# STM32N655 register map
File version: 1.0
CPU: CM55 r0p1, little endian, no MPU, FPU, vendor SysTick, 8 interrupt priority bits
Registers are 32-bit, read-write, reset 0x0 unless marked. A register's access mark holds for its fields unless they carry their own. Offsets are from the block's base; [hi:lo] are bit positions; {n}, {i} and the like mark numbered series; 'fields as' and 'values as' point back to an identical list.

## ETH — Ethernet address block description
Base 0x48036000
Same registers: ETH_S 0x58036000
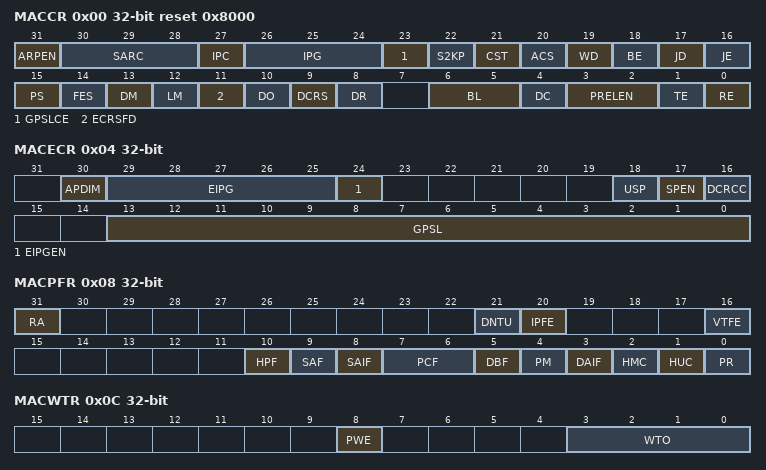
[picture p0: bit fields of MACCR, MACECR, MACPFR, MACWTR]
0x00 MACCR reset 0x8000 — Operating mode configuration register
  [31] ARPEN — ARP Offload Enable
  [30:28] SARC — Source Address Insertion or Replacement Control
  [27] IPC — Checksum Offload
  [26:24] IPG — Inter-Packet Gap
  [23] GPSLCE — Giant Packet Size Limit Control Enable
  [22] S2KP — IEEE 802.3as Support for 2K Packets
  [21] CST — CRC stripping for Type packets
  [20] ACS — Automatic Pad or CRC Stripping
  [19] WD — Watchdog Disable
  [18] BE — Packet Burst Enable
  [17] JD — Jabber Disable
  [16] JE — Jumbo Packet Enable
  [15] PS — Port Select
  [14] FES — MAC Speed
  [13] DM — Duplex Mode
  [12] LM — Loopback Mode
  [11] ECRSFD — Enable Carrier Sense Before Transmission in Full-duplex mode
  [10] DO — Disable Receive Own
  [9] DCRS — Disable Carrier Sense During Transmission
  [8] DR — Disable Retry
  [6:5] BL — Back-Off Limit
  [4] DC — Deferral Check
  [3:2] PRELEN — Preamble Length for Transmit packets
  [1] TE — Transmitter Enable
  [0] RE — Receiver Enable
0x04 MACECR — Extended operating mode configuration register
  [30] APDIM — ARP Packet Drop if IP Address Mismatch
  [29:25] EIPG — Extended Inter-Packet Gap
  [24] EIPGEN — Extended Inter-Packet Gap Enable
  [18] USP — Unicast Slow Protocol Packet Detect
  [17] SPEN — Slow Protocol Detection Enable
  [16] DCRCC — Disable CRC Checking for Received Packets
  [13:0] GPSL — Giant Packet Size Limit
0x08 MACPFR — Packet filtering control register
  [31] RA — Receive All
  [21] DNTU — Drop Non-TCP/UDP over IP Packets
  [20] IPFE — Layer 3 and Layer 4 Filter Enable
  [16] VTFE — VLAN Tag Filter Enable
  [10] HPF — Hash or Perfect Filter
  [9] SAF — Source Address Filter Enable
  [8] SAIF — SA Inverse Filtering
  [7:6] PCF — Pass Control Packets
  [5] DBF — Disable Broadcast Packets
  [4] PM — Pass All Multicast
  [3] DAIF — DA Inverse Filtering
  [2] HMC — Hash Multicast
  [1] HUC — Hash Unicast
  [0] PR — Promiscuous Mode
0x0C MACWTR — Watchdog timeout register
  [8] PWE — Programmable Watchdog Enable
  [3:0] WTO — Watchdog Timeout
0x10 MACHT0R — Hash Table 0 register
  [31:0] HT31T0 — MAC Hash Table First 32 Bits
0x14 MACHT1R — Hash Table 1 register
  [31:0] HT63T32 — MAC Hash Table Second 32 Bits
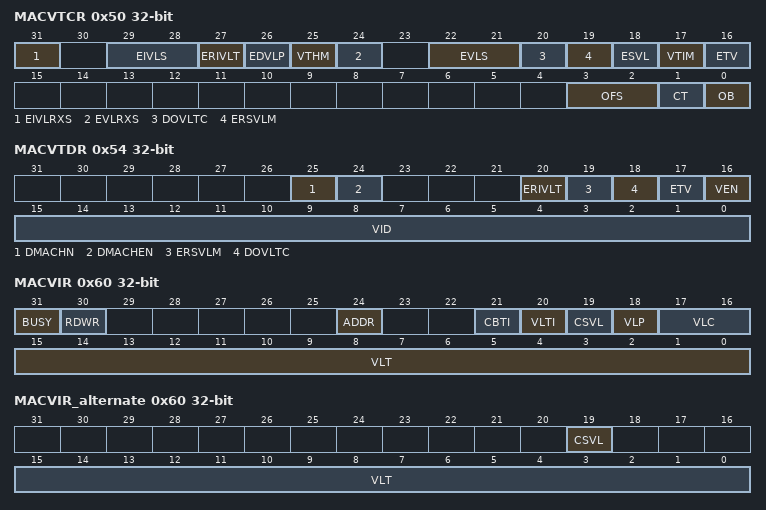
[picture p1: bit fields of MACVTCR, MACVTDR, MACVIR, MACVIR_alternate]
0x50 MACVTCR — VLAN tag Control register
  [31] EIVLRXS — Enable Inner VLAN Tag in Rx Status
  [29:28] EIVLS — Enable Inner VLAN Tag Stripping on Receive
  [27] ERIVLT — Enable Inner VLAN Tag
  [26] EDVLP — Enable Double VLAN Processing
  [25] VTHM — VLAN Tag Hash Table Match Enable
  [24] EVLRXS — Enable VLAN Tag in Rx status
  [22:21] EVLS — Enable VLAN Tag Stripping on Receive
  [20] DOVLTC — Disable VLAN Type Check
  [19] ERSVLM — Enable Receive S-VLAN Match
  [18] ESVL — Enable S-VLAN
  [17] VTIM — VLAN Tag Inverse Match Enable
  [16] ETV — Enable 12-Bit VLAN Tag Comparison
  [3:2] OFS — Offset
  [1] CT — Command Type
  [0] OB — Operation Busy
0x54 MACVTDR — VLAN tag data register
  [25] DMACHN — DMA Channel Number
  [24] DMACHEN — DMA Channel Number Enable
  [20] ERIVLT — Enable Inner VLAN Tag Comparison
  [19] ERSVLM — Enable S-VLAN Match for received Frames
  [18] DOVLTC — Disable VLAN Type Comparison
  [17] ETV — 12-bit or 16-bit VLAN comparison
  [16] VEN — VLAN Tag Enable
  [15:0] VID — VLAN Tag ID
0x58 MACVHTR — VLAN Hash table register
  [15:0] VLHT — VLAN Hash Table
0x60 MACVIR access per field — VLAN inclusion register
  [31] BUSY ro
  [30] RDWR rw — Read write control
  [24] ADDR rw — Address
  [21] CBTI rw — Channel based tag insertion
  [20] VLTI rw — VLAN Tag Input
  [19] CSVL rw — C-VLAN or S-VLAN
  [18] VLP rw — VLAN Priority Control
  [17:16] VLC rw — VLAN Tag Control in Transmit Packets
  [15:0] VLT rw — VLAN Tag for Transmit Packets
0x60 MACVIR_alternate (alternate view of MACVIR) — VLAN inclusion register
  [19] CSVL — C-VLAN or S-VLAN
  [15:0] VLT — VLAN Tag for Transmit Packets
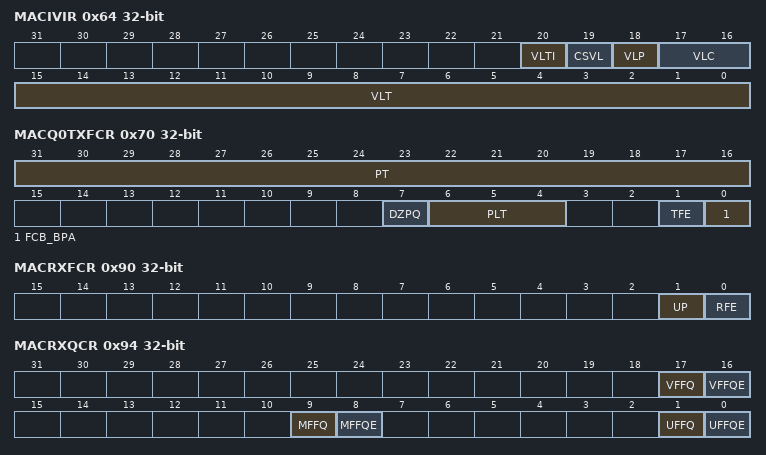
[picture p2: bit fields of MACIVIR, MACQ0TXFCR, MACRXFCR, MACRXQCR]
0x64 MACIVIR — Inner VLAN inclusion register
  [20] VLTI — VLAN Tag Input
  [19] CSVL — C-VLAN or S-VLAN
  [18] VLP — VLAN Priority Control
  [17:16] VLC — VLAN Tag Control in Transmit Packets
  [15:0] VLT — VLAN Tag for Transmit Packets
0x70 MACQ0TXFCR — Tx Queue 0 flow control register
  [31:16] PT — Pause Time
  [7] DZPQ — Disable Zero-Quanta Pause
  [6:4] PLT — Pause Low Threshold
  [1] TFE — Transmit Flow Control Enable
  [0] FCB_BPA — Flow Control Busy or Backpressure Activate
0x90 MACRXFCR — Rx flow control register
  [1] UP — Unicast Pause Packet Detect
  [0] RFE — Receive Flow Control Enable
0x94 MACRXQCR — Rx Queue control register
  [17] VFFQ — VLAN Tag Filter Fail Packets Queue
  [16] VFFQE — VLAN Tag Filter Fail Packets Queuing Enable
  [9] MFFQ — Multicast Address Filter Fail Packets Queue.
  [8] MFFQE — Multicast Address Filter Fail Packets Queuing Enable.
  [1] UFFQ — Unicast Address Filter Fail Packets Queue.
  [0] UFFQE — Unicast Address Filter Fail Packets Queuing Enable.
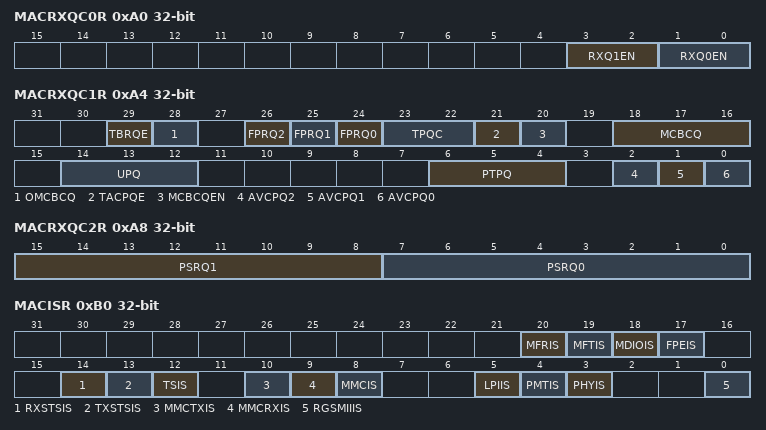
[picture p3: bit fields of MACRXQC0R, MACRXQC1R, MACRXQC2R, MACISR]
0xA0 MACRXQC0R — Rx queue control 0 register
  [3:2] RXQ1EN — Receive Queue 1 Enable
  [1:0] RXQ0EN — Receive Queue 0 Enable
0xA4 MACRXQC1R — Rx queue control 1 register
  [29] TBRQE — Type Field Based Rx Queuing Enable
  [28] OMCBCQ — Overriding MC-BC queue priority select
  [26] FPRQ2 — Frame Preemption Residue Queue
  [25] FPRQ1 — Frame Preemption Residue Queue
  [24] FPRQ0 — Frame Preemption Residue Queue
  [23:22] TPQC — Tagged PTP over Ethernet Packets Queuing Control
  [21] TACPQE — Tagged AV Control Packets Queuing Enable
  [20] MCBCQEN — Multicast and Broadcast Queue Enable
  [18:16] MCBCQ — Multicast and Broadcast Queue
  [14:12] UPQ — Untagged Packet Queue
  [6:4] PTPQ — PTP Packets Queue
  [2] AVCPQ2 — AV Untagged Control Packets Queue
  [1] AVCPQ1 — AV Untagged Control Packets Queue
  [0] AVCPQ0 — AV Untagged Control Packets Queue
0xA8 MACRXQC2R — Rx queue control 2 register
  [15:8] PSRQ1 — Priorities Selected in the Receive Queue 1
  [7:0] PSRQ0 — Priorities Selected in the Receive Queue 0
0xB0 MACISR access per field — Interrupt status register
  [20] MFRIS ro — MMC FPE Receive Interrupt Status
  [19] MFTIS ro — MMC FPE Transmit Interrupt Status
  [18] MDIOIS rw read-clears — MDIO Interrupt Status
  [17] FPEIS ro — Frame Preemption Interrupt Status
  [14] RXSTSIS rw read-clears — Receive Status Interrupt
  [13] TXSTSIS rw read-clears — Transmit Status Interrupt
  [12] TSIS rw read-clears — Timestamp Interrupt Status
  [10] MMCTXIS ro — MMC Transmit Interrupt Status
  [9] MMCRXIS ro — MMC Receive Interrupt Status
  [8] MMCIS ro — MMC Interrupt Status
  [5] LPIIS ro — LPI Interrupt Status
  [4] PMTIS ro — PMT Interrupt Status
  [3] PHYIS ro — PHY Interrupt
  [0] RGSMIIIS ro — RGMII Interrupt Status
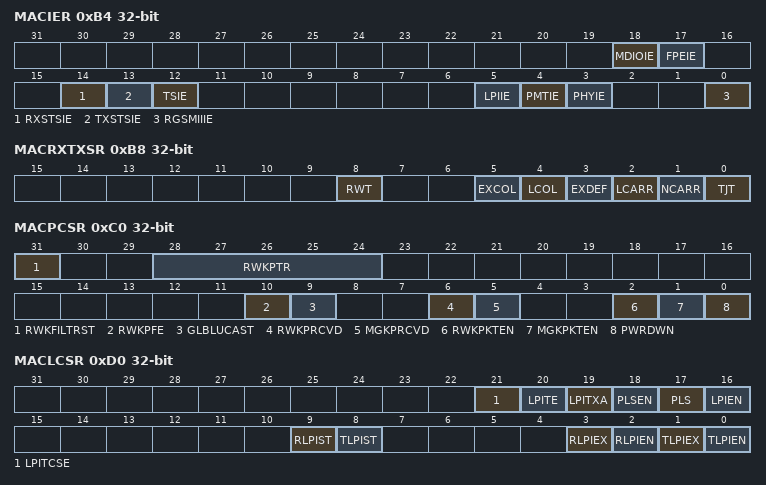
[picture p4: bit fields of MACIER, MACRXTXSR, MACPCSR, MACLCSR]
0xB4 MACIER — Interrupt enable register
  [18] MDIOIE — MDIO Interrupt Enable
  [17] FPEIE — Frame Preemption Interrupt Enable
  [14] RXSTSIE — Receive Status Interrupt Enable
  [13] TXSTSIE — Transmit Status Interrupt Enable
  [12] TSIE — Timestamp Interrupt Enable
  [5] LPIIE — LPI Interrupt Enable
  [4] PMTIE — PMT Interrupt Enable
  [3] PHYIE — PHY Interrupt Enable
  [0] RGSMIIIE — RGMII Interrupt Enable
0xB8 MACRXTXSR — Rx Tx status register
  [8] RWT read-clears — Receive Watchdog Timeout
  [5] EXCOL read-clears — Excessive Collisions
  [4] LCOL read-clears — Late Collision
  [3] EXDEF read-clears — Excessive Deferral
  [2] LCARR read-clears — Loss of Carrier
  [1] NCARR read-clears — No Carrier
  [0] TJT read-clears — Transmit Jabber Timeout
0xC0 MACPCSR access per field — PMT control status register
  [31] RWKFILTRST rw — Remote wake-up Packet Filter Register Pointer Reset
  [28:24] RWKPTR ro — Remote wake-up FIFO Pointer
  [10] RWKPFE rw — Remote wake-up Packet Forwarding Enable
  [9] GLBLUCAST rw — Global Unicast
  [6] RWKPRCVD ro — Remote wake-up Packet Received
  [5] MGKPRCVD rw read-clears — Magic Packet Received
  [2] RWKPKTEN rw — Remote wake-up Packet Enable
  [1] MGKPKTEN rw — Magic Packet Enable
  [0] PWRDWN rw — Power Down
0xC4 MACRWKPFR — Remote wake-up packet filter register
  [31:0] MACRWKPFR — Remote wake-up packet filter
0xD0 MACLCSR access per field — LPI control and status register
  [21] LPITCSE rw — LPI Tx Clock Stop Enable
  [20] LPITE rw — LPI Timer Enable
  [19] LPITXA rw — LPI Tx Automate
  [18] PLSEN rw — PHY Link Status Enable
  [17] PLS rw — PHY Link Status
  [16] LPIEN rw — LPI Enable
  [9] RLPIST ro — Receive LPI State
  [8] TLPIST ro — Transmit LPI State
  [3] RLPIEX ro — Receive LPI Exit
  [2] RLPIEN ro — Receive LPI Entry
  [1] TLPIEX ro — Transmit LPI Exit
  [0] TLPIEN ro — Transmit LPI Entry
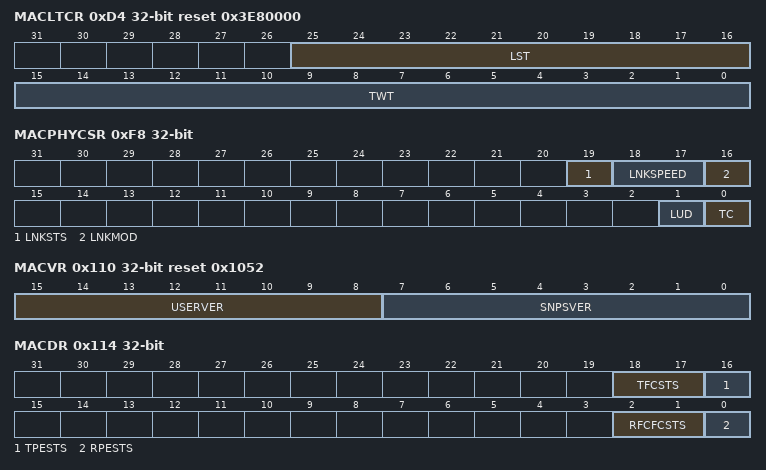
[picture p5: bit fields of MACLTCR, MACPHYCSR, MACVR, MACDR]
0xD4 MACLTCR reset 0x3E80000 — LPI timers control register
  [25:16] LST — LPI LS Timer
  [15:0] TWT — LPI TW Timer
0xD8 MACLETR — LPI entry timer register
  [19:0] LPIET — LPI Entry Timer
0xDC MAC1USTCR — One-microsecond-tick counter register
  [11:0] TIC_1US_CNTR — 1 s tick Counter
0xF8 MACPHYCSR access per field — PHYIF control status register
  [19] LNKSTS ro — Link Status
  [18:17] LNKSPEED ro — Link Speed
  [16] LNKMOD ro — Link Mode
  [1] LUD rw — Link Up or Down
  [0] TC rw — Transmit Configuration in RGMII
0x110 MACVR ro reset 0x1052 — Version register
  [15:8] USERVER — ST-defined version
  [7:0] SNPSVER — IP version
0x114 MACDR ro — Debug register
  [18:17] TFCSTS — MAC Transmit Packet Controller Status
  [16] TPESTS — MAC GMII or MII Transmit Protocol Engine Status
  [2:1] RFCFCSTS — MAC Receive Packet Controller FIFO Status
  [0] RPESTS — MAC GMII or MII Receive Protocol Engine Status
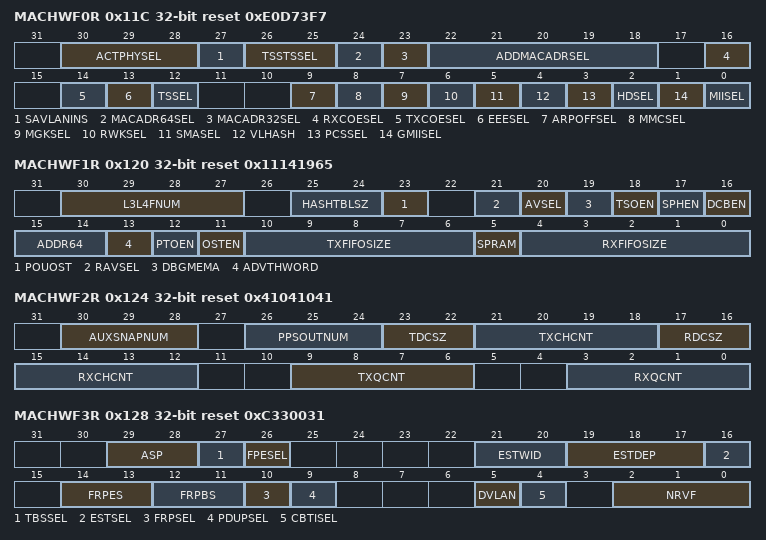
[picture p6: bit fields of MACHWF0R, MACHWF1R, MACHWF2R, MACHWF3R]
0x11C MACHWF0R ro reset 0xE0D73F7 — HW feature 0 register
  [30:28] ACTPHYSEL — Active PHY Selected
  [27] SAVLANINS — Source Address or VLAN Insertion Enable
  [26:25] TSSTSSEL — Timestamp System Time Source
  [24] MACADR64SEL — MAC Addresses 64-127 Selected
  [23] MACADR32SEL — MAC Addresses 32-63 Selected
  [22:18] ADDMACADRSEL — MAC Addresses 1-31 Selected
  [16] RXCOESEL — Receive Checksum Offload Enabled
  [14] TXCOESEL — Transmit Checksum Offload Enabled
  [13] EEESEL — Energy Efficient Ethernet Enabled
  [12] TSSEL — IEEE 1588-2008 Timestamp Enabled
  [9] ARPOFFSEL — ARP Offload Enabled
  [8] MMCSEL — RMON Module Enable
  [7] MGKSEL — PMT Magic Packet Enable
  [6] RWKSEL — PMT Remote wake-up Packet Enable
  [5] SMASEL — SMA (MDIO) Interface
  [4] VLHASH — VLAN Hash Filter Selected
  [3] PCSSEL — PCS Registers (TBI, SGMII, or RTBI PHY interface)
  [2] HDSEL — Half-duplex Support
  [1] GMIISEL — 1000 Mbps Support
  [0] MIISEL — 10 or 100 Mbps Support
0x120 MACHWF1R ro reset 0x11141965 — HW feature 1 register
  [30:27] L3L4FNUM — Total number of L3 or L4 Filters
  [25:24] HASHTBLSZ — Hash Table Size
  [23] POUOST — One Step for PTP over UDP/IP Feature Enable
  [21] RAVSEL — Rx Side Only AV Feature Enable
  [20] AVSEL — AV Feature Enable
  [19] DBGMEMA — DMA Debug Registers Enable
  [18] TSOEN — TCP Segmentation Offload Enable
  [17] SPHEN — Split Header Feature Enable
  [16] DCBEN — DCB Feature Enable
  [15:14] ADDR64 — Address width
  [13] ADVTHWORD — IEEE 1588 High Word Register Enable
  [12] PTOEN — PTP Offload Enable
  [11] OSTEN — One-Step Timestamping Enable
  [10:6] TXFIFOSIZE — MTL Transmit FIFO Size
  [5] SPRAM — Single Port RAM Enable
  [4:0] RXFIFOSIZE — MTL Receive FIFO Size
0x124 MACHWF2R ro reset 0x41041041 — HW feature 2 register
  [30:28] AUXSNAPNUM — Number of Auxiliary Snapshot Inputs
  [26:24] PPSOUTNUM — Number of PPS Outputs
  [23:22] TDCSZ — Tx DMA Descriptor Cache Size in terms of 16-byte descriptors
  [21:18] TXCHCNT — Number of DMA Transmit Channels
  [17:16] RDCSZ — Rx DMA Descriptor Cache Size in terms of 16-byte descriptors
  [15:12] RXCHCNT — Number of DMA Receive Channels
  [9:6] TXQCNT — Number of MTL Transmit Queues
  [3:0] RXQCNT — Number of MTL Receive Queues
0x128 MACHWF3R ro reset 0xC330031 — HW feature 3 register
  [29:28] ASP — Automotive Safety Package
  [27] TBSSEL — Time-based scheduling Enable
  [26] FPESEL — Frame Preemption Enable
  [21:20] ESTWID — Width of the Time Interval field in the Gate Control List
  [19:17] ESTDEP — Depth of the Gate Control List
  [16] ESTSEL — Enhancements to Scheduled Traffic Enable
  [14:13] FRPES — Flexible Receive Parser Table Entries size
  [12:11] FRPBS — Flexible Receive Parser Buffer size
  [10] FRPSEL — Flexible Receive Parser Selected
  [9] PDUPSEL — Broadcast/Multicast Packet Duplication
  [5] DVLAN — Double VLAN processing enable
  [4] CBTISEL — Queue/Channel based VLAN tag insertion on Tx enable
  [2:0] NRVF — Number of Extended VLAN Tag Filters Enabled
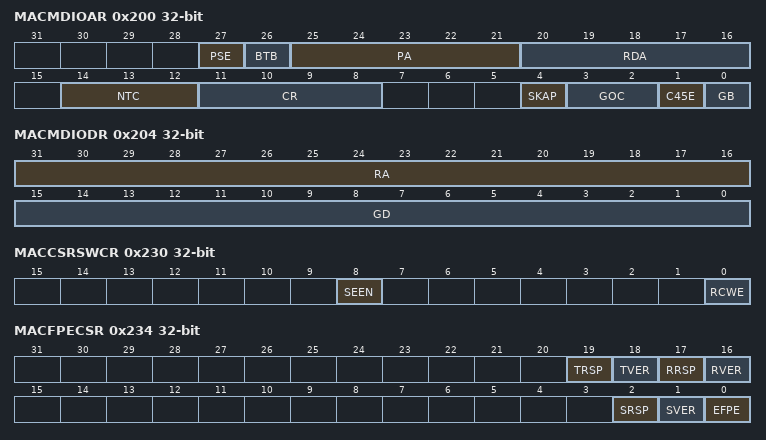
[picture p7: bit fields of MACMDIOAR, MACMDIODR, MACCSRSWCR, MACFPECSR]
0x200 MACMDIOAR — MDIO address register
  [27] PSE — Preamble Suppression Enable
  [26] BTB — Back to Back transactions
  [25:21] PA — Physical Layer Address
  [20:16] RDA — Register/Device Address
  [14:12] NTC — Number of Training Clocks
  [11:8] CR — CSR Clock Range
  [4] SKAP — Skip Address Packet
  [3:2] GOC — GMII Operation Command
  [1] C45E — Clause 45 PHY Enable
  [0] GB — GMII Busy
0x204 MACMDIODR — MDIO data register
  [31:16] RA — Register Address
  [15:0] GD — GMII Data
0x210 MACARPAR — ARP address register
  [31:0] ARPPA — ARP Protocol Address
0x230 MACCSRSWCR — CSR software control register
  [8] SEEN — Slave Error Response Enable
  [0] RCWE — Register Clear on Write 1 Enable
0x234 MACFPECSR — FPE control and status register
  [19] TRSP read-clears — Transmitted Respond Frame
  [18] TVER read-clears — Transmitted Verify Frame
  [17] RRSP read-clears — Received Respond Frame
  [16] RVER read-clears — Received Verify Frame
  [2] SRSP — Send Respond mPacket
  [1] SVER — Send Verify mPacket
  [0] EFPE — Enable Tx Frame Preemption
0x240 MACPRSTIMR — MAC presentation time register
  [31:0] MPTN — MAC 1722 Presentation Time in ns
0x244 MACPRSTIMUR — MAC presentation time update register
  [31:0] MPTU — MAC 1722 Presentation Time Update
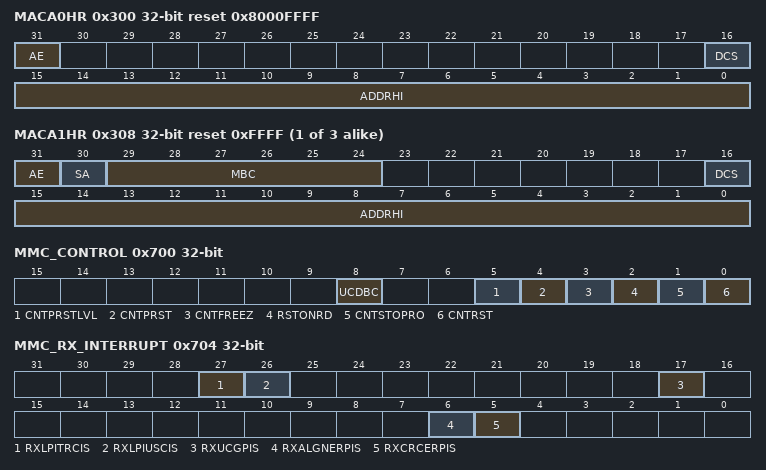
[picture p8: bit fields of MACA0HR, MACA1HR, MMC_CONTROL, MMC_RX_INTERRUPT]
0x300 MACA0HR access per field reset 0x8000FFFF — MAC Address 0 high register
  [31] AE ro — Address Enable
  [16] DCS rw — DMA Channel Select
  [15:0] ADDRHI rw — MAC Address0[47:32]
{0x304+8i} MACA{i}LR reset 0xFFFFFFFF (i=0..3) — MAC Address {i} low register
  [31:0] ADDRLO — MAC Address x [31:0]
{0x300+8i} MACA{i}HR reset 0xFFFF (i=1..3) — MAC Address {i} high register
  [31] AE — Address Enable
  [30] SA — Source Address
  [29:24] MBC — Mask Byte Control
  [16] DCS — DMA Channel Select
  [15:0] ADDRHI — MAC Address1 [47:32]
0x700 MMC_CONTROL
  [8] UCDBC — Update MMC Counters for Dropped Broadcast Packets
  [5] CNTPRSTLVL — Full-Half Preset
  [4] CNTPRST — Counters Preset
  [3] CNTFREEZ — MMC Counter Freeze
  [2] RSTONRD — Reset on Read
  [1] CNTSTOPRO — Counter Stop Rollover
  [0] CNTRST — Counters Reset
0x704 MMC_RX_INTERRUPT
  [27] RXLPITRCIS read-clears — MMC Receive LPI transition counter interrupt status
  [26] RXLPIUSCIS read-clears — MMC Receive LPI microsecond counter interrupt status
  [17] RXUCGPIS read-clears — MMC Receive Unicast Good Packet Counter Interrupt Status
  [6] RXALGNERPIS read-clears — MMC Receive Alignment Error Packet Counter Interrupt Status
  [5] RXCRCERPIS read-clears — MMC Receive CRC Error Packet Counter Interrupt Status
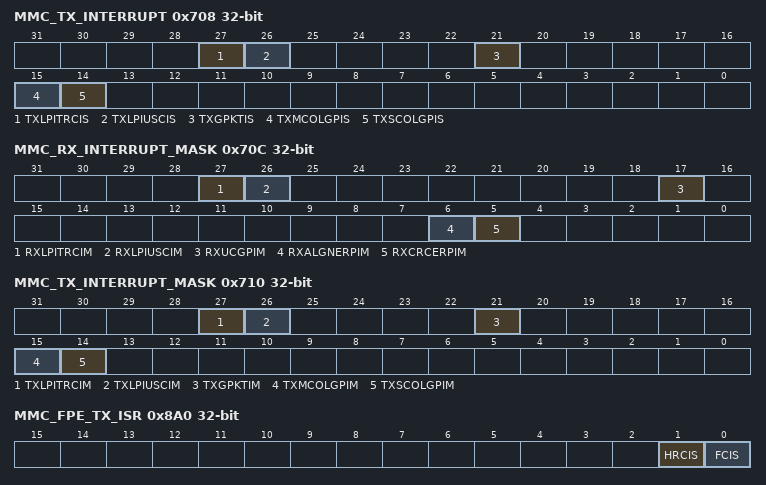
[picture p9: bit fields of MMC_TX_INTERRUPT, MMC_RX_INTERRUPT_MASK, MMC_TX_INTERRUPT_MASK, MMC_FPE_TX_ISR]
0x708 MMC_TX_INTERRUPT
  [27] TXLPITRCIS read-clears — MMC Transmit LPI transition counter interrupt status
  [26] TXLPIUSCIS read-clears — MMC Transmit LPI microsecond counter interrupt status
  [21] TXGPKTIS read-clears — MMC Transmit Good Packet Counter Interrupt Status
  [15] TXMCOLGPIS read-clears — MMC Transmit Multiple Collision Good Packet Counter Interrupt Status
  [14] TXSCOLGPIS read-clears — MMC Transmit Single Collision Good Packet Counter Interrupt Status
0x70C MMC_RX_INTERRUPT_MASK
  [27] RXLPITRCIM — MMC Receive LPI transition counter interrupt Mask
  [26] RXLPIUSCIM — MMC Receive LPI microsecond counter interrupt Mask
  [17] RXUCGPIM — MMC Receive Unicast Good Packet Counter Interrupt Mask
  [6] RXALGNERPIM — MMC Receive Alignment Error Packet Counter Interrupt Mask
  [5] RXCRCERPIM — MMC Receive CRC Error Packet Counter Interrupt Mask
0x710 MMC_TX_INTERRUPT_MASK
  [27] TXLPITRCIM — MMC Transmit LPI transition counter interrupt Mask
  [26] TXLPIUSCIM — MMC Transmit LPI microsecond counter interrupt Mask
  [21] TXGPKTIM — MMC Transmit Good Packet Counter Interrupt Mask
  [15] TXMCOLGPIM — MMC Transmit Multiple Collision Good Packet Counter Interrupt Mask
  [14] TXSCOLGPIM — MMC Transmit Single Collision Good Packet Counter Interrupt Mask
0x74C TX_SINGLE_COLLISION_GOOD_PACKETS ro
  [31:0] TXSNGLCOLG — Tx Single Collision Good Packets
0x750 TX_MULTIPLE_COLLISION_GOOD_PACKETS ro
  [31:0] TXMULTCOLG — Tx Multiple Collision Good Packets
0x768 TX_PACKET_COUNT_GOOD ro
  [31:0] TXPKTG — Tx Packet Count Good
0x794 RX_CRC_ERROR_PACKETS ro
  [31:0] RXCRCERR — Rx CRC Error Packets
0x798 RX_ALIGNMENT_ERROR_PACKETS ro
  [31:0] RXALGNERR — Rx Alignment Error Packets
0x7C4 RX_UNICAST_PACKETS_GOOD ro
  [31:0] RXUCASTG — Rx Unicast Packets Good
0x7EC TX_LPI_USEC_CNTR ro — Tx LPI microsecond timer register
  [31:0] TXLPIUSC — Tx LPI Microseconds Counter
0x7F0 TX_LPI_TRAN_CNTR ro — Tx LPI transition counter register
  [31:0] TXLPITRC — Tx LPI Transition counter
0x7F4 RX_LPI_USEC_CNTR ro — Rx LPI microsecond counter register
  [31:0] RXLPIUSC — Rx LPI Microseconds Counter
0x7F8 RX_LPI_TRAN_CNTR ro — Rx LPI transition counter register
  [31:0] RXLPITRC — Rx LPI Transition counter
0x8A0 MMC_FPE_TX_ISR — MMC FPE Tx interrupt status register
  [1] HRCIS read-clears — MMC Tx Hold Request Counter Interrupt Status
  [0] FCIS read-clears — MMC Tx FPE Fragment Counter Interrupt status
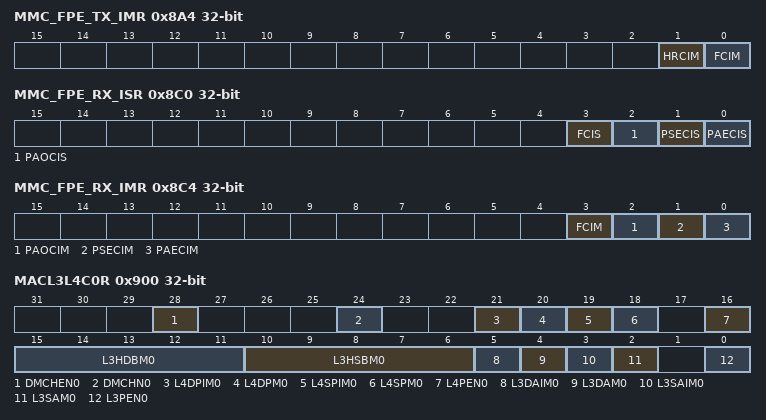
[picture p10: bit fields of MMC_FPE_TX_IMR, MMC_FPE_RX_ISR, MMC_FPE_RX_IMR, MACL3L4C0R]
0x8A4 MMC_FPE_TX_IMR — MMC FPE Tx interrupt mask register
  [1] HRCIM — MMC Transmit Hold Request Counter Interrupt Mask
  [0] FCIM — MMC Transmit Fragment Counter Interrupt Mask
0x8A8 MMC_FPE_TX_FCR ro — MMC FPE Tx fragment counter register
  [31:0] TXFFC — Tx FPE Fragment counter
0x8AC MMC_TX_HRCR ro — MMC Tx hold request counter register
  [31:0] TXHRC — Tx Hold Request Counter
0x8C0 MMC_FPE_RX_ISR ro — MMC FPE Rx interrupt status register
  [3] FCIS — MMC Rx FPE Fragment Counter Interrupt Status
  [2] PAOCIS — MMC Rx Packet Assembly OK Counter Interrupt Status
  [1] PSECIS — MMC Rx Packet SMD Error Counter Interrupt Status
  [0] PAECIS — MMC Rx Packet Assembly Error Counter Interrupt Status
0x8C4 MMC_FPE_RX_IMR — MMC FPE Rx interrupt mask register
  [3] FCIM — MMC Rx FPE Fragment Counter Interrupt Mask
  [2] PAOCIM — MMC Rx Packet Assembly OK Counter Interrupt Mask
  [1] PSECIM — MMC Rx Packet SMD Error Counter Interrupt Mask
  [0] PAECIM — MMC Rx Packet Assembly Error Counter Interrupt Mask
0x8C8 RX_PACKET_ASM_ERR ro — MMC Rx packet assembly error register
  [31:0] PAEC — Rx Packet Assembly Error Counter
0x8CC RX_PACKET_SMD_ERR ro — MMC Rx packet SMD error register
  [31:0] PSEC — Rx Packet SMD Error Counter
0x8D0 RX_PACKET_ASM_OKR ro — MMC Rx packet assembly OK register
  [31:0] PAOC — Rx Packet Assembly OK Counter
0x8D4 RX_FPE_FRAG_CR ro — MMC Rx FPE fragments counter register
  [31:0] FFC — Rx FPE Fragment Counter
0x900 MACL3L4C0R — L3 and L4 control 0 register
  [28] DMCHEN0 — DMA Channel Select Enable
  [24] DMCHN0 — DMA Channel Number
  [21] L4DPIM0 — Layer 4 Destination Port Inverse Match Enable
  [20] L4DPM0 — Layer 4 Destination Port Match Enable
  [19] L4SPIM0 — Layer 4 Source Port Inverse Match Enable
  [18] L4SPM0 — Layer 4 Source Port Match Enable
  [16] L4PEN0 — Layer 4 Protocol Enable
  [15:11] L3HDBM0 — Layer 3 IP DA higher bits match
  [10:6] L3HSBM0 — Layer 3 IP SA higher bits match
  [5] L3DAIM0 — Layer 3 IP DA Inverse Match Enable
  [4] L3DAM0 — Layer 3 IP DA Match Enable
  [3] L3SAIM0 — Layer 3 IP SA Inverse Match Enable
  [2] L3SAM0 — Layer 3 IP SA Match Enable
  [0] L3PEN0 — Layer 3 Protocol Enable
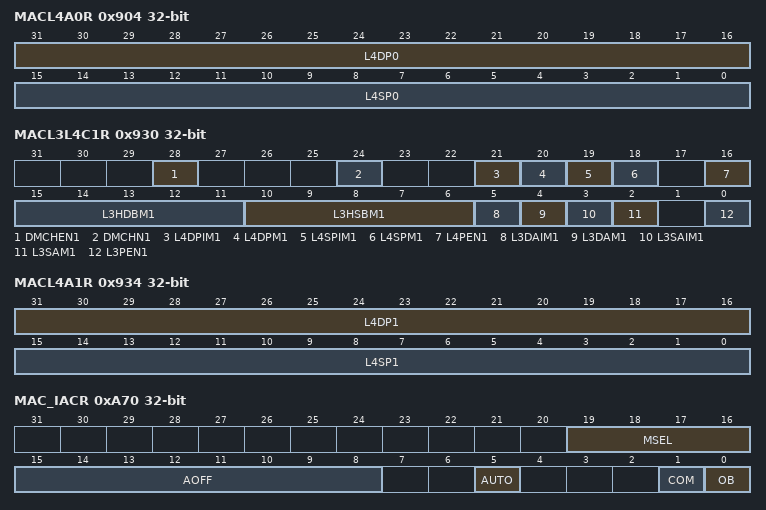
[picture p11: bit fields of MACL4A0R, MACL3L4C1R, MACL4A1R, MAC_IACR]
0x904 MACL4A0R — Layer4 Address filter 0 register
  [31:16] L4DP0 — Layer 4 Destination Port Number Field
  [15:0] L4SP0 — Layer 4 Source Port Number Field
0x910 MACL3A00R — Layer3 Address 0 filter 0 register
  [31:0] L3A00 — Layer 3 Address 0 Field
0x914 MACL3A10R — Layer3 Address 1 filter 0 register
  [31:0] L3A10 — Layer 3 Address 1 Field
0x918 MACL3A20R — Layer3 Address 2 filter 0 register
  [31:0] L3A20 — Layer 3 Address 2 Field
0x91C MACL3A30R — Layer3 Address 3 filter 0 register
  [31:0] L3A30 — Layer 3 Address 3 Field
0x930 MACL3L4C1R — L3 and L4 control 1 register
  [28] DMCHEN1 — DMA Channel Select Enable
  [24] DMCHN1 — DMA Channel Number
  [21] L4DPIM1 — Layer 4 Destination Port Inverse Match Enable
  [20] L4DPM1 — Layer 4 Destination Port Match Enable
  [19] L4SPIM1 — Layer 4 Source Port Inverse Match Enable
  [18] L4SPM1 — Layer 4 Source Port Match Enable
  [16] L4PEN1 — Layer 4 Protocol Enable
  [15:11] L3HDBM1 — Layer 3 IP DA higher bits match
  [10:6] L3HSBM1 — Layer 3 IP SA Higher Bits Match
  [5] L3DAIM1 — Layer 3 IP DA Inverse Match Enable
  [4] L3DAM1 — Layer 3 IP DA Match Enable
  [3] L3SAIM1 — Layer 3 IP SA Inverse Match Enable
  [2] L3SAM1 — Layer 3 IP SA Match Enable
  [0] L3PEN1 — Layer 3 Protocol Enable
0x934 MACL4A1R — Layer 4 address filter 1 register
  [31:16] L4DP1 — Layer 4 Destination Port Number Field
  [15:0] L4SP1 — Layer 4 Source Port Number Field
0x940 MACL3A01R — Layer3 address 0 filter 1 Register
  [31:0] L3A01 — Layer 3 Address 0 Field
0x944 MACL3A11R — Layer3 address 1 filter 1 register
  [31:0] L3A11 — Layer 3 Address 1 Field
0x948 MACL3A21R — Layer3 address 2 filter 1 Register
  [31:0] L3A21 — Layer 3 Address 2 Field
0x94C MACL3A31R — Layer3 address 3 filter 1 register
  [31:0] L3A31 — Layer 3 Address 3 Field
0xA70 MAC_IACR — MAC Indirect Access Control register
  [19:16] MSEL — Mode Select
  [15:8] AOFF — Address Offset
  [5] AUTO — Auto-increment
  [1] COM — Command type
  [0] OB — Operation Busy.
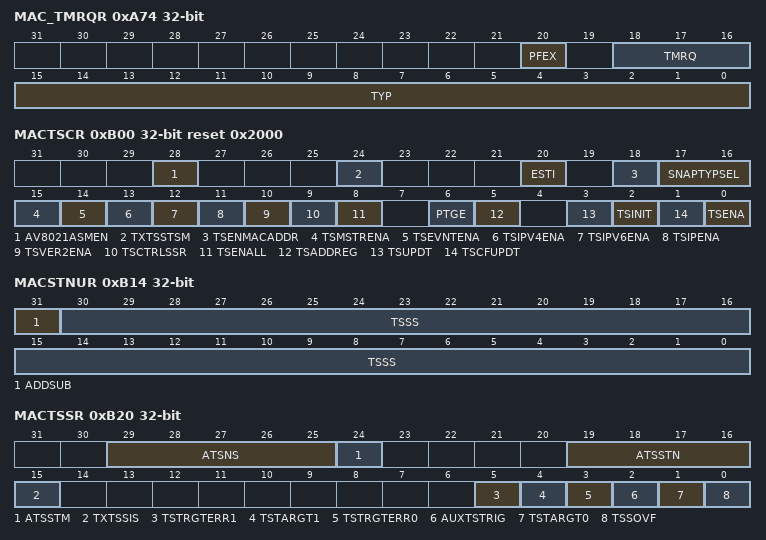
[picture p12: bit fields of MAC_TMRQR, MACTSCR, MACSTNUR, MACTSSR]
0xA74 MAC_TMRQR — MAC type-based Rx Queue mapping register
  [20] PFEX — Preemption or Express Packet
  [18:16] TMRQ — Type Match Rx Queue Number
  [15:0] TYP — Type field Value
0xB00 MACTSCR reset 0x2000 — Timestamp control Register
  [28] AV8021ASMEN — AV 802.1AS Mode Enable
  [24] TXTSSTSM — Transmit Timestamp Status Mode
  [20] ESTI — External System Time Input
  [18] TSENMACADDR — Enable MAC Address for PTP Packet Filtering
  [17:16] SNAPTYPSEL — Select PTP packets for Taking Snapshots
  [15] TSMSTRENA — Enable Snapshot for Messages Relevant to Master
  [14] TSEVNTENA — Enable Timestamp Snapshot for Event Messages
  [13] TSIPV4ENA — Enable Processing of PTP Packets Sent over IPv4-UDP
  [12] TSIPV6ENA — Enable Processing of PTP Packets Sent over IPv6-UDP
  [11] TSIPENA — Enable Processing of PTP over Ethernet Packets
  [10] TSVER2ENA — Enable PTP Packet Processing for Version 2 Format
  [9] TSCTRLSSR — Timestamp Digital or Binary Rollover Control
  [8] TSENALL — Enable Timestamp for All Packets
  [6] PTGE — Presentation Time Generation Enable
  [5] TSADDREG — Update Addend Register
  [3] TSUPDT — Update Timestamp
  [2] TSINIT — Initialize Timestamp
  [1] TSCFUPDT — Fine or Coarse Timestamp Update
  [0] TSENA — Enable Timestamp
0xB04 MACSSIR — Subsecond increment register
  [23:16] SSINC — Subsecond Increment Value
0xB08 MACSTSR ro — System time seconds register
  [31:0] TSS — Timestamp Second
0xB0C MACSTNR ro — System time nanoseconds register
  [30:0] TSSS — Timestamp subseconds
0xB10 MACSTSUR — System time seconds update register
  [31:0] TSS — Timestamp Seconds
0xB14 MACSTNUR — System time nanoseconds update register
  [31] ADDSUB — Add or Subtract Time
  [30:0] TSSS — Timestamp subseconds
0xB18 MACTSAR — Timestamp addend register
  [31:0] TSAR — Timestamp Addend Register
0xB20 MACTSSR access per field — Timestamp status register
  [29:25] ATSNS ro — Number of Auxiliary Timestamp Snapshots
  [24] ATSSTM rw read-clears — Auxiliary Timestamp Snapshot Trigger Missed
  [19:16] ATSSTN rw read-clears — Auxiliary Timestamp Snapshot Trigger Identifier
  [15] TXTSSIS rw read-clears — Tx Timestamp Status Interrupt Status
  [5] TSTRGTERR1 rw read-clears — Timestamp Target Time Error
  [4] TSTARGT1 rw read-clears — Timestamp Target Time Reached
  [3] TSTRGTERR0 rw read-clears — Timestamp Target Time Error
  [2] AUXTSTRIG rw read-clears — Auxiliary Timestamp Trigger Snapshot
  [1] TSTARGT0 rw read-clears — Timestamp Target Time Reached
  [0] TSSOVF rw read-clears — Timestamp Seconds Overflow
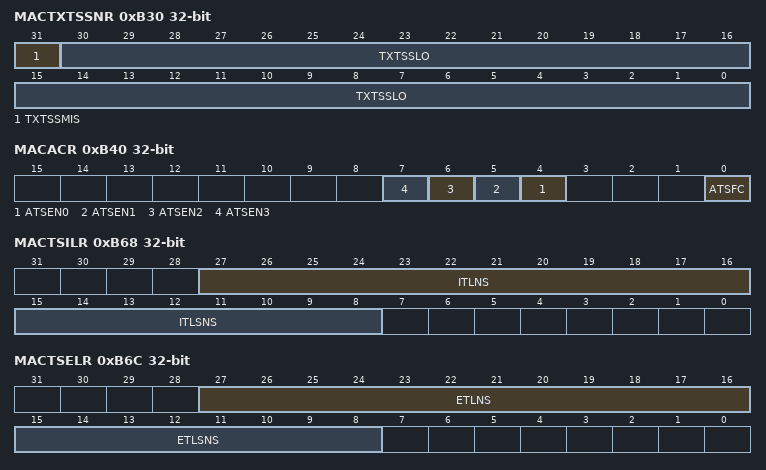
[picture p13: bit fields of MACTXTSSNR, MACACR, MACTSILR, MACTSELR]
0xB30 MACTXTSSNR access per field — Tx timestamp status nanoseconds register
  [31] TXTSSMIS ro — Transmit Timestamp Status Missed
  [30:0] TXTSSLO rw read-clears — Transmit Timestamp Status Low
0xB34 MACTXTSSSR ro — Tx timestamp status seconds register
  [31:0] TXTSSHI — Transmit Timestamp Status High
0xB40 MACACR — Auxiliary control register
  [n+4] ATSEN{n} (n=0..3) — Auxiliary Snapshot {n} Enable
  [0] ATSFC — Auxiliary Snapshot FIFO Clear
0xB48 MACATSNR ro — Auxiliary timestamp nanoseconds register
  [30:0] AUXTSLO — Auxiliary Timestamp
0xB4C MACATSSR ro — Auxiliary timestamp seconds register
  [31:0] AUXTSHI — Auxiliary Timestamp
0xB50 MACTSIACR — Timestamp Ingress asymmetric correction register
  [31:0] OSTIAC — One-Step Timestamp Ingress Asymmetry Correction
0xB54 MACTSEACR — Timestamp Egress asymmetric correction register
  [31:0] OSTEAC — One-Step Timestamp Egress Asymmetry Correction
0xB58 MACTSICNR — Timestamp Ingress correction nanosecond register
  [31:0] TSIC — Timestamp Ingress Correction
0xB5C MACTSECNR — Timestamp Egress correction nanosecond register
  [31:0] TSEC — Timestamp Egress Correction
0xB68 MACTSILR ro — Timestamp Ingress Latency register
  [27:16] ITLNS — Ingress Timestamp Latency, in nanoseconds
  [15:8] ITLSNS — Ingress Timestamp Latency, in subnanoseconds
0xB6C MACTSELR ro — Timestamp Egress Latency register
  [27:16] ETLNS — Egress Timestamp Latency, in nanoseconds
  [15:8] ETLSNS — Egress Timestamp Latency, in subnanoseconds
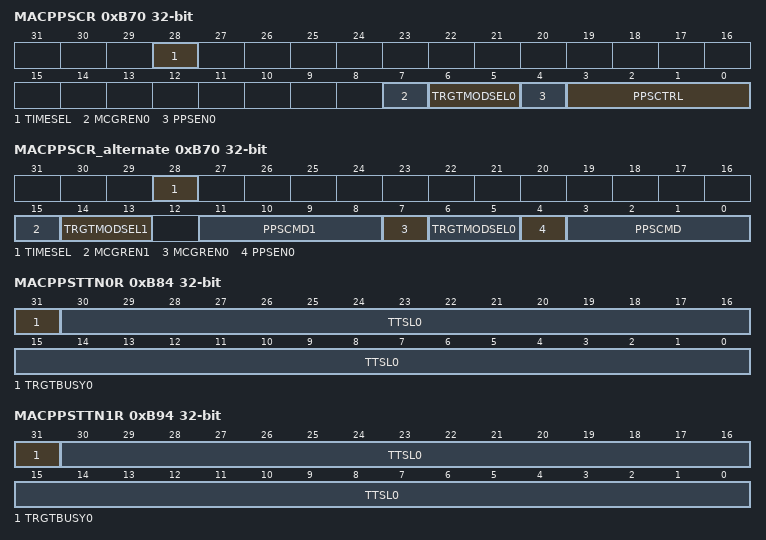
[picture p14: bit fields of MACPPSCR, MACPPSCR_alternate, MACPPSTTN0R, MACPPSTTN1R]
0xB70 MACPPSCR — PPS control register
  [28] TIMESEL — Time Select
  [7] MCGREN0 — MCGR Mode Enable for PPS0 Output
  [6:5] TRGTMODSEL0 — Target Time Register Mode for PPS Output
  [4] PPSEN0 — Flexible PPS Output Mode Enable
  [3:0] PPSCTRL — PPS Output Frequency Control
0xB70 MACPPSCR_alternate (alternate view of MACPPSCR) — PPS control register
  [28] TIMESEL — Time Select
  [15] MCGREN1 — MCGR Mode Enable for PPS Output 1
  [14:13] TRGTMODSEL1 — Target Time Register Mode for PPS Output 1
  [11:8] PPSCMD1 — Flexible PPS Output 1 Control
  [7] MCGREN0 — MCGR Mode Enable for PPS Output 0
  [6:5] TRGTMODSEL0 — Target Time Register Mode for PPS Output 0
  [4] PPSEN0 — Flexible PPS Output 0 Mode Enable
  [3:0] PPSCMD — Flexible PPS Output 0 (eth_ptp_pps_out) Control
0xB80 MACPPSTTS0R — PPS 0 target time seconds register
  [31:0] TSTRH0 — PPS Target Time Seconds Register
0xB84 MACPPSTTN0R — PPS 0 target time nanoseconds register
  [31] TRGTBUSY0 — PPS Target Time Register Busy
  [30:0] TTSL0 — Target Time Low for PPS Register
0xB88 MACPPSI0R — PPS 0 interval register
  [31:0] PPSINT0 — PPS Output Signal Interval
0xB8C MACPPSW0R — PPS 0 width register
  [31:0] PPSWIDTH0 — PPS Output Signal Width
0xB90 MACPPSTTS1R — PPS 1 target time seconds register
  [31:0] TSTRH0 — PPS Target Time Seconds Register
0xB94 MACPPSTTN1R — PPS 1 target time nanoseconds register
  fields as MACPPSTTN0R
0xB98 MACPPSI1R — PPS 1 interval register
  [31:0] PPSINT0 — PPS Output Signal Interval
0xB9C MACPPSW1R — PPS 1 width register
  [31:0] PPSWIDTH0 — PPS Output Signal Width
0xBC0 MACPOCR — PTP Offload control register
  [15:8] DN — Domain Number
  [7] PDRDIS — Disable Peer Delay Response response generation
  [6] DRRDIS — Disable PTO Delay Request/Response response generation
  [5] APDREQTRIG — Automatic PTP Pdelay_Req message Trigger
  [4] ASYNCTRIG — Automatic PTP SYNC message Trigger
  [2] APDREQEN — Automatic PTP Pdelay_Req message Enable
  [1] ASYNCEN — Automatic PTP SYNC message Enable
  [0] PTOEN — PTP Offload Enable
0xBC4 MACSPI0R — PTP Source Port Identity 0 Register
  [31:0] SPI0 — Source Port Identity 0
0xBC8 MACSPI1R — PTP Source port identity 1 register
  [31:0] SPI1 — Source Port Identity 1
0xBCC MACSPI2R — PTP Source port identity 2 register
  [15:0] SPI2 — Source Port Identity 2
0xBD0 MACLMIR — Log message interval register
  [31:24] LMPDRI — Log Min Pdelay_Req Interval
  [10:8] DRSYNCR — Delay_Req to SYNC Ratio
  [7:0] LSI — Log Sync Interval
0xC00 MTLOMR — Operating mode Register
  [9] CNTCLR — Counters Reset
  [8] CNTPRST — Counters Preset
  [6:5] SCHALG — Tx Scheduling Algorithm
  [2] RAA — Receive Arbitration Algorithm
  [1] DTXSTS — Drop Transmit Status
0xC20 MTLISR ro — Interrupt status Register
  [18] ESTIS — EST (TAS- 802.1Qbv) Interrupt Status
  [1] Q1IS — Queue 1 interrupt status
  [0] Q0IS — Queue 0 interrupt status
0xC30 MTLRXQDMAMR — Rx Queue and DMA Channel Mapping Register
  [12] Q1DDMACH — Queue 1 Enabled for DA-based DMA Channel Selection
  [8] Q1MDMACH — Queue 1 Mapped to DMA Channel
  [4] Q0DDMACH — Queue 0 Enabled for DA-based DMA Channel Selection
  [0] Q0MDMACH — Queue 0 Mapped to DMA Channel
0xC40 MTLTBSCR — TBS control register
  [31:8] LEOS — Launch Expiry Offset
  [6:4] LEGOS — Launch Expiry GSN Offset
  [1] LEOV — Launch expiry offset valid
  [0] ESTM — EST offset mode
0xC50 MTLESTCR — EST Control Register
  [31:24] PTOV — PTP Time Offset Value
  [23:12] CTOV — Current Time Offset Value
  [10:8] TILS — Time Interval Left Shift Amount
  [7:6] LCSE — Loop Count to report Scheduling Error
  [5] DFBS — Drop Frames causing Scheduling Error
  [4] DDBF — Do not Drop frames during Frame Size Error
  [1] SSWL — Switch to S/W owned list
  [0] EEST — Enable EST
0xC54 MTLESTECR — EST Extended Control Register
  [5:0] OVHD — Overhead Bytes Value
0xC58 MTLESTSR access per field — EST Status Register
  [19:16] CGSN ro — Current GCL slot number
  [15:8] BTRL ro — BTR Error Loop Count
  [7] SWOL ro — S/W owned list
  [4] CGCE rw — Constant Gate Control Error
  [3] HLBS ro — Head-Of-Line Blocking due to Scheduling
  [2] HLBF ro — Head-Of-Line Blocking due to Frame Size
  [1] BTRE rw — BTR Error
  [0] SWLC rw — Switch to S/W owned list Complete
0xC60 MTLESTSCHER — EST Schedule Error Register
  [1:0] SEQN — Schedule Error Queue Number
0xC64 MTLESTFSER — EST Frame size Error Register
  [1:0] FEQN — Frame Size Error Queue Number
0xC68 MTLESTFSCR ro — EST Frame size Capture Register
  [16] HBFQ — Queue Number of HLBF
  [14:0] HBFS — Frame Size of HLBF
0xC70 MTLESTIER — EST Interrupt Enable Register
  [4] CGCE — Interrupt Enable for CGCE
  [3] IEHS — Interrupt Enable for HLBS
  [2] IEHF — Interrupt Enable for HLBF
  [1] IEBE — Interrupt Enable for BTR Error
  [0] IECC — Interrupt Enable for Switch List
0xC80 MTLESTGCLCR — EST Gate Control List Register
  [13:8] ADDR — Gate Control List Address:
  [5] DBGB — Debug Mode Bank Select
  [4] DBGM — Debug Mode
  [2] GCRR — Gate Control Related Registers
  [1] R1W0 — Read 1, Write 0
  [0] SRWO — Start Read/Write Operation
0xC84 MTLESTGCLDR — EST Gate Control List Data Register
  [31:0] GCD — Gate Control Data
0xC90 MTLFPECSR — FPE Frame Preemption Control Status Register
  [28] HRS — Hold/Release Status
  [9:8] PEC — Preemption Classification
  [1:0] AFSZ — Additional Fragment Size
0xC94 MTLFPEAR — FPE Frame Preemption Advance Register
  [31:16] RADV — Release Advance
  [15:0] HADV — Hold Advance
0xD00 MTLTXQ0OMR — T0 queue 0 operating mode Register
  [19:16] TQS — Transmit queue size
  [6:4] TTC — Transmit Threshold Control
  [3:2] TXQEN — Transmit Queue Enable
  [1] TSF — Transmit Store and Forward
  [0] FTQ — Flush Transmit Queue
0xD04 MTLTXQ0UR — T0 queue 0 underflow register
  [11] UFCNTOVF read-clears — Overflow Bit for Underflow Packet Counter
  [10:0] UFFRMCNT read-clears — Underflow Packet Counter
0xD08 MTLTXQ0DR ro — T0 queue 0 debug register
  [22:20] STXSTSF — Number of Status Words in Tx Status FIFO of Queue
  [18:16] PTXQ — Number of Packets in the Transmit Queue
  [5] TXSTSFSTS — MTL Tx Status FIFO Full Status
  [4] TXQSTS — MTL Tx Queue Not Empty Status
  [3] TWCSTS — MTL Tx Queue Write Controller Status
  [2:1] TRCSTS — MTL Tx Queue Read Controller Status
  [0] TXQPAUSED — Transmit Queue in Pause
0xD14 MTLTXQ0ESR ro — T0 queue 0 ETS status Register
  [23:0] ABS — Average Bits per Slot
0xD18 MTLTXQ0QWR — Tx queue 0 quantum weight register
  [6:0] ISCQW — Weights
0xD2C MTLQ0ICSR — Queue 0 interrupt control status Register
  [24] RXOIE — Receive Queue Overflow Interrupt Enable
  [16] RXOVFIS — Receive Queue Overflow Interrupt Status
  [9] ABPSIE — Average Bits Per Slot Interrupt Enable
  [8] TXUIE — Transmit Queue Underflow Interrupt Enable
  [1] ABPSIS — Average Bits Per Slot Interrupt Status
  [0] TXUNFIS — Transmit Queue Underflow Interrupt Status
0xD30 MTLRXQ0OMR — R0 queue 0 operating mode register
  [23:20] RQS — Receive Queue Size
  [16:14] RFD — Threshold for Deactivating Flow Control (in Half-duplex and Full-duplex modes)
  [10:8] RFA — Threshold for Activating Flow Control (in Half-duplex and Full-duplex)
  [7] EHFC — Enable Hardware Flow Control
  [6] DIS_TCP_EF — Disable Dropping of TCP/IP Checksum Error Packets
  [5] RSF — Receive Queue Store and Forward
  [4] FEP — Forward Error Packets
  [3] FUP — Forward Undersized Good Packets
  [1:0] RTC — Receive Queue Threshold Control
0xD34 MTLRXQ0MPOCR — R0 queue 0 missed packet and overflow counter register
  [27] MISCNTOVF read-clears — Missed Packet Counter Overflow Bit
  [26:16] MISPKTCNT read-clears — Missed Packet Counter
  [11] OVFCNTOVF read-clears — Overflow Counter Overflow Bit
  [10:0] OVFPKTCNT read-clears — Overflow Packet Counter
0xD38 MTLRXQ0DR ro — R0 queue 0 debug register
  [29:16] PRXQ — Number of Packets in Receive Queue
  [5:4] RXQSTS — MTL Rx Queue Fill-Level Status
  [2:1] RRCSTS — MTL Rx Queue Read Controller State
  [0] RWCSTS — MTL Rx Queue Write Controller Active Status
0xD3C MTLRXQ0CR — R0 queue 0 control register
  [3] RXQ_FRM_ARBIT — Receive Queue Packet Arbitration
  [2:0] RXQ_WEGT — Receive Queue Weight
0xD40 MTLTXQ1OMR — T1 queue 1 operating mode Register
  fields as MTLTXQ0OMR
0xD44 MTLTXQ1UR — T1 queue 1 underflow register
  fields as MTLTXQ0UR
0xD48 MTLTXQ1DR ro — T1 queue 1 debug register
  fields as MTLTXQ0DR
0xD50 MTLTXQ1ECR — Tx queue 1 ETS control Register
  [6:4] SLC — Slot Count
  [3] CC — Credit Control
  [2] AVALG — AV Algorithm
0xD54 MTLTXQ1ESR ro — T1 queue 1 ETS status Register
  [23:0] ABS — Average Bits per Slot
0xD58 MTLTXQ1QWR — Tx queue 1 quantum weight register
  [13:0] ISCQW — IdleSlopeCredit or Weights
0xD5C MTLTXQ1SSCR — Tx queue 1 send slope credit Register
  [13:0] SSC — sendSlopeCredit Value
0xD60 MTLTXQ1HCR — Tx Queue 1 hiCredit register
  [28:0] HC — hiCredit Value
0xD64 MTLTXQ1LCR — Tx queue 1 loCredit register
  [28:0] LC — loCredit Value
0xD6C MTLQ1ICSR — Queue 1 interrupt control status Register
  fields as MTLQ0ICSR
0xD70 MTLRXQ1OMR — R1 queue 1 operating mode register
  fields as MTLRXQ0OMR
0xD74 MTLRXQ1MPOCR — R1 queue 1 missed packet and overflow counter register
  fields as MTLRXQ0MPOCR
0xD78 MTLRXQ1DR ro — R1 queue 1 debug register
  fields as MTLRXQ0DR
0xD7C MTLRXQ1CR — R1 queue 1 control register
  fields as MTLRXQ0CR
0x1000 DMAMR access per field — DMA mode register
  [17:16] INTM rw — Interrupt Mode
  [11] TXPR rw — Transmit priority
  [8] DSPW rw — Descriptor Posted Write
  [4:2] TAA ro — Transmit Arbitration Algorithm
  [0] SWR rw — Software Reset
0x1004 DMASBMR reset 0x1010000 — System bus mode register
  [31] EN_LPI — Enable Low Power Interface (LPI)
  [30] LPI_XIT_PKT — Unlock on Magic Packet or Remote wake-up packet
  [25:24] WR_OSR_LMT — AXI Maximum Write Outstanding Request Limit
  [17:16] RD_OSR_LMT — AXI Maximum Read Outstanding Request Limit
  [13] ONEKBBE — 1 Kbyte Boundary Crossing Enable for the AXI Master
  [12] AAL — Address-Aligned Beats
  [10] AALE — Automatic AXI LPI enable
  [7] BLEN256 — AXI Burst Length 256
  [6] BLEN128 — AXI Burst Length 128
  [5] BLEN64 — AXI Burst Length 64
  [4] BLEN32 — AXI Burst Length 32
  [3] BLEN16 — AXI Burst Length 16
  [2] BLEN8 — AXI Burst Length 8
  [1] BLEN4 — AXI Burst Length 4
  [0] FB — Fixed Burst Length
0x1008 DMAISR ro — Interrupt status register
  [17] MACIS — MAC Interrupt Status
  [16] MTLIS — MTL Interrupt Status
  [1] DC1IS — DMA Channel 1 Interrupt Status
  [0] DC0IS — DMA Channel 0 Interrupt Status
0x100C DMADSR ro — Debug status register
  [23:20] TPS1 — DMA Channel 1 Transmit Process State
  [19:16] RPS1 — DMA Channel 1 Receive Process State
  [15:12] TPS0 — DMA Channel 0 Transmit Process State
  [11:8] RPS0 — DMA Channel 0 Receive Process State
  [1] AXRHSTS — AXI Master Read Channel Status
  [0] AXWHSTS — AXI Master Write Channel
0x1020 DMAA4TXACR — AXI4 transmit channel ACE control register
  [19:16] THC — Transmit DMA First Packet Buffer or TSO Header Cache Control
  [11:8] TEC — Transmit DMA Extended Packet Buffer or TSO Payload Cache Control
  [3:0] TDRC — Transmit DMA Read Descriptor Cache Control
0x1024 DMAA4RXACR — AXI4 receive channel ACE control register
  [27:24] RDC — Receive DMA Buffer Cache Control
  [19:16] RHC — Receive DMA Header Cache Control
  [11:8] RPC — Receive DMA Payload Cache Control
  [3:0] RDWC — Receive DMA Write Descriptor Cache Control
0x1028 DMAA4DACR — AXI4 descriptor ACE control register
  [11:8] RDRC — Receive DMA Read Descriptor Cache control
  [5:4] TDWD — Transmit DMA Write Descriptor Domain control
  [3:0] TDWC — Transmit DMA Write Descriptor Cache control
0x1040 DMALPIEI — AXI4 LPI Entry Interval register
  [3:0] LPIEI — LPI Entry Interval
0x1050 DMATBSCTRL0R — DMA TBS control register 0
  [31:8] FTOS — Fetch time offset
  [6:4] FGOS — Fetch GSN offset
  [0] FTOV — Fetch time offset valid
0x1100 DMAC0CR — Channel 0 control register
  [20:18] DSL — Descriptor Skip Length
  [16] PBLX8 — 8xPBL mode
  [13:0] MSS — Maximum Segment Size
0x1104 DMAC0TXCR access per field — Channel 0 transmit control register
  [28] EDSE rw — Enhanced Descriptor Enable
  [27:24] TQOS rw — Transmit QOS
  [21:16] TXPBL rw — Transmit Programmable Burst Length
  [15] IPBL rw — Ignore PBL Requirement
  [12] TSE rw — TCP Segmentation Enabled
  [4] OSF rw — Operate on Second Packet
  [3:1] TCW ro — Transmit Channel Weight
  [0] ST rw — Start or Stop Transmission Command
0x1108 DMAC0RXCR — Channel 0 receive control register
  [31] RPF — DMA Rx Channel x Packet Flush
  [27:24] RQOS — Rx AXI4 QOS.
  [21:16] RXPBL — Receive Programmable Burst Length
  [14:1] RBSZ — Receive Buffer size
  [0] SR — Start or Stop Receive
0x1114 DMAC0TXDLAR — Channel 0 T0 descriptor list address register
  [31:0] TDESLA — Start of Transmit List
0x111C DMAC0RXDLAR — Channel 0 Rx descriptor list address register
  [31:0] RDESLA — Start of Receive List
0x1120 DMAC0TXDTPR — Channel 0 T0 descriptor tail pointer register
  [31:0] TDT — Transmit Descriptor Tail Pointer
0x1128 DMAC0RXDTPR — Channel 0 R0 descriptor tail pointer register
  [31:0] RDT — Receive Descriptor Tail Pointer
0x112C DMAC0TXRLR — Channel 0 T0 descriptor ring length register
  [9:0] TDRL — Transmit Descriptor Ring Length
0x1130 DMAC0RXRLR — Channel 0 R0 descriptor ring length register
  [23:17] ARBS — Alternate Receive Buffer Size
  [9:0] RDRL — Receive Descriptor Ring Length
0x1134 DMAC0IER — Channel 0 interrupt enable register
  [15] NIE — Normal Interrupt Summary Enable
  [14] AIE — Abnormal Interrupt Summary Enable
  [13] CDEE — Context Descriptor Error Enable
  [12] FBEE — Fatal Bus Error Enable
  [11] ERIE — Early Receive Interrupt Enable
  [10] ETIE — Early Transmit Interrupt Enable
  [9] RWTE — Receive Watchdog Timeout Enable
  [8] RSE — Receive Stopped Enable
  [7] RBUE — Receive Buffer Unavailable Enable
  [6] RIE — Receive Interrupt Enable
  [2] TBUE — Transmit Buffer Unavailable Enable
  [1] TXSE — Transmit Stopped Enable
  [0] TIE — Transmit Interrupt Enable
0x1138 DMAC0RXIWTR — Channel 0 R0 interrupt watchdog timer register
  [17:16] RWTU — Receive Interrupt Watchdog Timer Count Units
  [7:0] RWT — Receive Interrupt Watchdog Timer Count
0x113C DMAC0SFCSR access per field reset 0x7C0 — Channel 0 slot function control status register
  [19:16] RSN ro — Reference Slot Number
  [15:4] SIV rw — Slot Interval Value
  [1] ASC rw — Advance Slot Check
  [0] ESC rw — Enable Slot Comparison
0x1144 DMAC0CATXDR ro — Channel 0 current application transmit descriptor register
  [31:0] CURTDESAPTR — Application Transmit Descriptor Address Pointer
0x114C DMAC0CARXDR ro — Channel 0 current application receive descriptor register
  [31:0] CURRDESAPTR — Application Receive Descriptor Address Pointer
0x1154 DMAC0CATXBR ro — Channel 0 current application transmit buffer register
  [31:0] CURTBUFAPTR — Application Transmit Buffer Address Pointer
0x115C DMAC0CARXBR ro — Channel 0 current application receive buffer register
  [31:0] CURRBUFAPTR — Application Receive Buffer Address Pointer
0x1160 DMAC0SR access per field — Channel 0 status register
  [21:19] REB ro — Rx DMA Error Bits
  [18:16] TEB ro — Tx DMA Error Bits
  [15] NIS rw — Normal Interrupt Summary
  [14] AIS rw — Abnormal Interrupt Summary
  [13] CDE rw — Context Descriptor Error
  [12] FBE rw — Fatal Bus Error
  [11] ERI rw — Early Receive Interrupt
  [10] ETI rw — Early Transmit Interrupt
  [9] RWT rw — Receive Watchdog Timeout
  [8] RPS rw — Receive Process Stopped
  [7] RBU rw — Receive Buffer Unavailable
  [6] RI rw — Receive Interrupt
  [2] TBU rw — Transmit Buffer Unavailable
  [1] TPS rw — Transmit Process Stopped
  [0] TI rw — Transmit Interrupt
0x1164 DMAC0MFCR — Channel 0 missed frame count register
  [15] MFCO read-clears — Overflow status of the MFC Counter
  [10:0] MFC read-clears — Dropped Packet Counters
0x1180 DMAC1CR — Channel 1 control register
  fields as DMAC0CR
0x1184 DMAC1TXCR access per field — Channel 1 transmit control register
  fields as DMAC0TXCR
0x1188 DMAC1RXCR — Channel 1 receive control register
  fields as DMAC0RXCR
0x1194 DMAC1TXDLAR — Channel 1 T1 descriptor list address register
  [31:0] TDESLA — Start of Transmit List
0x11A0 DMAC1TXDTPR — Channel 1 T1 descriptor tail pointer register
  [31:0] TDT — Transmit Descriptor Tail Pointer
0x11A8 DMAC1RXDTPR — Channel 1 R1 descriptor tail pointer register
  [31:0] RDT — Receive Descriptor Tail Pointer
0x11AC DMAC1TXRLR — Channel 1 T1 descriptor ring length register
  [9:0] TDRL — Transmit Descriptor Ring Length
0x11B0 DMAC1RXRLR — Channel 1 R1 descriptor ring length register
  fields as DMAC0RXRLR
0x11B4 DMAC1IER — Channel 1 interrupt enable register
  fields as DMAC0IER
0x11B8 DMAC1RXIWTR — Channel 1 R1 interrupt watchdog timer register
  fields as DMAC0RXIWTR
0x11BC DMAC1SFCSR access per field reset 0x7C0 — Channel 1 slot function control status register
  fields as DMAC0SFCSR
0x11C4 DMAC1CATXDR ro — Channel 1 current application transmit descriptor register
  [31:0] CURTDESAPTR — Application Transmit Descriptor Address Pointer
0x11CC DMAC1CARXDR ro — Channel 1 current application receive descriptor register
  [31:0] CURRDESAPTR — Application Receive Descriptor Address Pointer
0x11D4 DMAC1CATXBR ro — Channel 1 current application transmit buffer register
  [31:0] CURTBUFAPTR — Application Transmit Buffer Address Pointer
0x11DC DMAC1CARXBR ro — Channel 1 current application receive buffer register
  [31:0] CURRBUFAPTR — Application Receive Buffer Address Pointer
0x11E0 DMAC1SR access per field — Channel 1 status register
  fields as DMAC0SR
0x11E4 DMAC1MFCR — Channel 1 missed frame count register
  fields as DMAC0MFCR
